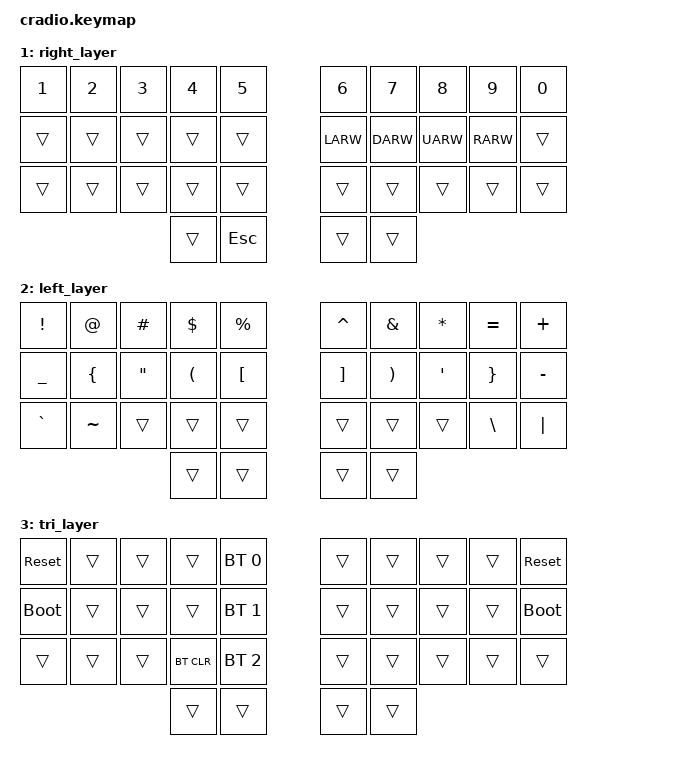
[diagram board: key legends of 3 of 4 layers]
// Copyright (c) 2022 The ZMK Contributors
// SPDX-License-Identifier: MIT

#include <behaviors.dtsi>
#include <dt-bindings/zmk/keys.h>
#include <dt-bindings/zmk/bt.h>

// Home row mods macro
#define HRML(k1,k2,k3,k4) &ht LSHFT k1  &ht LALT k2  &ht LCTRL k3  &ht LGUI k4
#define HRMR(k1,k2,k3,k4) &ht RGUI k1  &ht RCTRL k2  &ht RALT k3  &ht RSHFT k4

/ {
    behaviors {
        ht: hold_tap {
            compatible = "zmk,behavior-hold-tap";
            #binding-cells = <2>;
            flavor = "tap-preferred";
            tapping-term-ms = <220>;
            quick-tap-ms = <150>;
            require-prior-idle-ms = <100>;
            bindings = <&kp>, <&kp>;
        };
    };

    conditional_layers {
        compatible = "zmk,conditional-layers";
        tri_layer {
            if-layers = <1 2>;
            then-layer = <3>;
        };
    };

    keymap {
        compatible = "zmk,keymap";
        default_layer {
            bindings = <
        //╭──────────┬──────────┬──────────┬──────────┬──────────╮   ╭──────────┬──────────┬──────────┬──────────┬──────────╮
        //│  Q       │  W       │  E       │  R       │  T       │   │  Y       │  U       │  I       │  O       │  P       │
            &kp Q      &kp W      &kp E      &kp R      &kp T          &kp Y      &kp U      &kp I      &kp O      &kp P
        //├──────────┼──────────┼──────────┼──────────┼──────────┤   ├──────────┼──────────┼──────────┼──────────┼──────────┤
        //│  A       │  S       │  D       │  F       │  G       │   │  H       │  J       │  K       │  L       │ ; :      │
            HRML(A,        S,         D,         F)     &kp G          &kp H      HRMR(J,        K,         L,        SEMI)
        //├──────────┼──────────┼──────────┼──────────┼──────────┤   ├──────────┼──────────┼──────────┼──────────┼──────────┤
        //│  Z       │  X       │  C       │  V       │  B       │   │  N       │  M       │ , <      │ . >      │ / ?      │
            &kp Z      &kp X      &kp C      &kp V      &kp B          &kp N      &kp M      &kp COMMA  &kp DOT    &kp FSLH
        //╰──────────┴──────────┴──────────┼──────────┼──────────┤   ├──────────┼──────────┼──────────┴──────────┴──────────╯
                                            &lt 2 TAB   &kp ENTER     &kp SPACE  &lt 1 BSPC
        //                                 ╰──────────┴──────────╯   ╰──────────┴──────────╯
            >;
        };

        right_layer {
            bindings = <
        //╭──────────┬──────────┬──────────┬──────────┬──────────╮   ╭──────────┬──────────┬──────────┬──────────┬──────────╮
        //│ 1        │  2       │  3       │  4       │  5       │   │ 6        │  7       │ 8        │ 9        │  0       │
            &kp N1      &kp N2     &kp N3     &kp N4     &kp N5        &kp N6    &kp N7      &kp N8     &kp N9      &kp N0 
        //├──────────┼──────────┼──────────┼──────────┼──────────┤   ├──────────┼──────────┼──────────┼──────────┼──────────┤
        //│          │          │          │          │          │   │ LEFT     │ DOWN     │ UP       │ RIGHT    │          │
            &trans     &trans      &trans    &trans      &trans         &kp LARW   &kp DARW   &kp UARW   &kp RARW   &trans 
        //├──────────┼──────────┼──────────┼──────────┼──────────┤   ├──────────┼──────────┼──────────┼──────────┼──────────┤
        //│          │          │          │          │          │   │          │          │          │          │          │
           &trans      &trans     &trans      &trans    &trans          &trans     &trans     &trans     &trans     &trans
        //╰──────────┴──────────┴──────────┼──────────┼──────────┤   ├──────────┼──────────┼──────────┴──────────┴──────────╯
                                             &trans     &kp ESC        &trans     &trans
        //                                 ╰──────────┴──────────╯   ╰──────────┴──────────╯
            >;
        };

        left_layer {
            bindings = <
        //╭──────────┬──────────┬──────────┬──────────┬──────────╮   ╭──────────┬──────────┬──────────┬──────────┬──────────╮
        //│  !       │  @       │  #       │  $       │  %       │   │  ^       │  &       │  *       │  =       │  +       │
            &kp EXCL   &kp AT    &kp HASH   &kp DLLR   &kp PRCNT      &kp CARET  &kp AMPS   &kp ASTRK   &kp EQUAL  &kp PLUS
        //├──────────┼──────────┼──────────┼──────────┼──────────┤   ├──────────┼──────────┼──────────┼──────────┼──────────┤
        //│  _       │  {       │   "      │   (      │  [       │   │  ]       │  )       │  '       │  }       │  -       │
           &kp UNDER  &kp LBRC    &kp DQT    &kp LPAR   &kp LBKT      &kp RBKT   &kp RPAR   &kp SQT    &kp RBRC  &kp MINUS
        //├──────────┼──────────┼──────────┼──────────┼──────────┤   ├──────────┼──────────┼──────────┼──────────┼──────────┤
        //│  `       │  ~       │          │          │          │   │          │          │          │   \      │  |       │
           &kp GRAVE  &kp TILDE   &trans     &trans     &trans         &trans     &trans      &trans   &kp BSLH   &kp PIPE
        //╰──────────┴──────────┴──────────┼──────────┼──────────┤   ├──────────┼──────────┼──────────┴──────────┴──────────╯
                                             &trans     &trans         &trans     &trans
        //                                 ╰──────────┴──────────╯   ╰──────────┴──────────╯
            >;
        };

        tri_layer {
            bindings = <
        //╭──────────┬──────────┬──────────┬──────────┬──────────╮   ╭──────────┬──────────┬──────────┬──────────┬──────────╮
        //│ RESET    │          │          │          │PROFILE 0 │   │          │          │          │          │  RESET   │
           &sys_reset  &trans     &trans     &trans    &bt BT_SEL 0    &trans     &trans     &trans     &trans    &sys_reset
        //├──────────┼──────────┼──────────┼──────────┼──────────┤   ├──────────┼──────────┼──────────┼──────────┼──────────┤
        //│BOOTLOADER│          │          │          │PROFILE 1 │   │          │          │          │          │BOOTLOADER│
          &bootloader  &trans     &trans     &trans    &bt BT_SEL 1    &trans     &trans     &trans     &trans    &bootloader
        //├──────────┼──────────┼──────────┼──────────┼──────────┤   ├──────────┼──────────┼──────────┼──────────┼──────────┤
        //│          │          │          │ CLEAR BT │PROFILE 2 │   │          │          │          │          │          │
            &trans     &trans     &trans    &bt BT_CLR &bt BT_SEL 2    &trans     &trans     &trans     &trans     &trans
        //╰──────────┴──────────┴──────────┼──────────┼──────────┤   ├──────────┼──────────┼──────────┴──────────┴──────────╯
                                             &trans     &trans         &trans     &trans
        //                                 ╰──────────┴──────────╯   ╰──────────┴──────────╯
            >;
        };
    };
};
